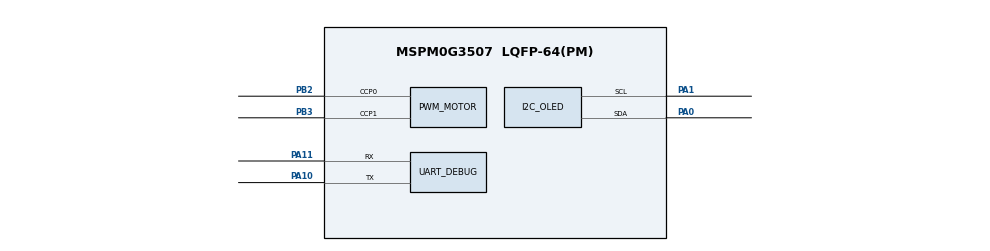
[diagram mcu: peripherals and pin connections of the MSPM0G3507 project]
/**
 * H2026 Q2 MSPM0G3507 peripheral ownership.
 *
 * This is a new hardware configuration for the frozen C07A/S27F-S28A
 * vehicle.  It is intentionally unrelated to the old generic-car SysConfig.
 */
//@cliArgs --device "MSPM0G350X" --package "LQFP-64(PM)" --part "Default"
//@v2CliArgs --device "MSPM0G3507" --package "LQFP-64(PM)"
// @cliArgs --board /ti/boards/LP_MSPM0G3507 --rtos nortos

const GPIO   = scripting.addModule("/ti/driverlib/GPIO", {}, false);
const PWM    = scripting.addModule("/ti/driverlib/PWM", {}, false);
const TIMER  = scripting.addModule("/ti/driverlib/TIMER", {}, false);
const UART   = scripting.addModule("/ti/driverlib/UART", {}, false);
const ADC12  = scripting.addModule("/ti/driverlib/ADC12", {}, false);
const I2C    = scripting.addModule("/ti/driverlib/I2C", {}, false);
const SYSCTL = scripting.addModule("/ti/driverlib/SYSCTL");

const PWM_MOTOR = PWM.addInstance();
const TIMER_CONTROL = TIMER.addInstance();
const UART_DEBUG = UART.addInstance();
const ADC_LINE_SENSOR = ADC12.addInstance();
const I2C_OLED = I2C.addInstance();

const GPIO_ENCODER_LEFT  = GPIO.addInstance();
const GPIO_ENCODER_RIGHT = GPIO.addInstance();
const GPIO_MOTOR_DIR     = GPIO.addInstance();
const GPIO_UI            = GPIO.addInstance();
const GPIO_LINE_MUX = GPIO.addInstance();

const Board = scripting.addModule("/ti/driverlib/Board", {}, false);

SYSCTL.forceDefaultClkConfig = true;
SYSCTL.clockTreeEn = true;

/* Integrated D103A/TB6612: PWMA/PWMB plus two GPIO direction pairs. */
PWM_MOTOR.$name = "PWM_MOTOR";
PWM_MOTOR.clockPrescale = 1;
PWM_MOTOR.timerCount = 8000;
PWM_MOTOR.timerStartTimer = false;
PWM_MOTOR.peripheral.$assign = "TIMA1";
PWM_MOTOR.peripheral.ccp0Pin.$assign = "PB2";
PWM_MOTOR.peripheral.ccp1Pin.$assign = "PB3";
PWM_MOTOR.PWM_CHANNEL_0.$name = "TB_A_PWM";
PWM_MOTOR.PWM_CHANNEL_0.dutyCycle = 0;
PWM_MOTOR.PWM_CHANNEL_1.$name = "TB_B_PWM";
PWM_MOTOR.PWM_CHANNEL_1.dutyCycle = 0;

/* Hard 5 ms scheduler source.  ISR only records pending/overrun counters. */
TIMER_CONTROL.$name = "TIMER_CONTROL";
TIMER_CONTROL.profile = "Basic_Periodic";
TIMER_CONTROL.timerPeriod = "5 ms";
TIMER_CONTROL.timerStartTimer = false;
TIMER_CONTROL.peripheral.$assign = "TIMG7";

/* CD4051 eight-channel gray board: AD2=PA12, AD1=PA27, AD0=PB16, OUT=PB17. */
GPIO_LINE_MUX.$name = "GPIO_LINE_MUX";
GPIO_LINE_MUX.associatedPins.create(3);
GPIO_LINE_MUX.associatedPins[0].$name = "LINE_AD2";
GPIO_LINE_MUX.associatedPins[0].assignedPort = "PORTA";
GPIO_LINE_MUX.associatedPins[0].assignedPin = "12";
GPIO_LINE_MUX.associatedPins[0].initialValue = "CLEARED";
GPIO_LINE_MUX.associatedPins[1].$name = "LINE_AD1";
GPIO_LINE_MUX.associatedPins[1].assignedPort = "PORTA";
GPIO_LINE_MUX.associatedPins[1].assignedPin = "27";
GPIO_LINE_MUX.associatedPins[1].initialValue = "CLEARED";
GPIO_LINE_MUX.associatedPins[2].$name = "LINE_AD0";
GPIO_LINE_MUX.associatedPins[2].assignedPort = "PORTB";
GPIO_LINE_MUX.associatedPins[2].assignedPin = "16";
GPIO_LINE_MUX.associatedPins[2].initialValue = "CLEARED";

ADC_LINE_SENSOR.$name = "ADC_LINE_SENSOR";
ADC_LINE_SENSOR.sampClkSrc = "DL_ADC12_CLOCK_ULPCLK";
ADC_LINE_SENSOR.sampClkDiv = "DL_ADC12_CLOCK_DIVIDE_8";
ADC_LINE_SENSOR.adcMem0chansel = "DL_ADC12_INPUT_CHAN_4";
/* Default supports the 1.2 ms scan budget; validate after any divider fit. */
ADC_LINE_SENSOR.sampleTime0 = "1us";
ADC_LINE_SENSOR.powerDownMode = "DL_ADC12_POWER_DOWN_MODE_MANUAL";
ADC_LINE_SENSOR.peripheral.$assign = "ADC1";
ADC_LINE_SENSOR.peripheral.adcPin4.$assign = "PB17";

/* External four-pin OLED and the retained MPU6050 share I2C0 safely. */
I2C_OLED.$name = "I2C_OLED";
I2C_OLED.basicEnableController = true;
I2C_OLED.basicControllerBusSpeed = 400000;
I2C_OLED.advAnalogGlitchFilter = "DISABLED";
I2C_OLED.peripheral.$assign = "I2C0";
I2C_OLED.peripheral.sdaPin.$assign = "PA0";
I2C_OLED.peripheral.sclPin.$assign = "PA1";

UART_DEBUG.$name = "UART_DEBUG";
UART_DEBUG.enableFIFO = true;
UART_DEBUG.enableDMARX = false;
UART_DEBUG.enableDMATX = false;
UART_DEBUG.targetBaudRate = 115200;
/* Dedicated debug serial path; it does not share the line-sensor bus. */
UART_DEBUG.peripheral.$assign = "UART0";
UART_DEBUG.peripheral.txPin.$assign = "PA10";
UART_DEBUG.peripheral.rxPin.$assign = "PA11";


/*
 * Both encoder phases use GPIO rise/fall interrupts (four-edge decoding).
 * C07A/S27F logical left is TB6612 channel B (PB20/PB24); logical right is
 * channel A (PA25/PA26).  This follows the bench-verified wheel mapping.
 */
GPIO_ENCODER_LEFT.$name = "GPIO_ENCODER_LEFT";
GPIO_ENCODER_LEFT.port = "PORTB";
GPIO_ENCODER_LEFT.associatedPins.create(2);
GPIO_ENCODER_LEFT.associatedPins[0].$name = "LEFT_A";
GPIO_ENCODER_LEFT.associatedPins[0].assignedPin = "20";
GPIO_ENCODER_LEFT.associatedPins[0].direction = "INPUT";
GPIO_ENCODER_LEFT.associatedPins[0].interruptEn = true;
GPIO_ENCODER_LEFT.associatedPins[0].polarity = "RISE_FALL";
GPIO_ENCODER_LEFT.associatedPins[1].$name = "LEFT_B";
GPIO_ENCODER_LEFT.associatedPins[1].assignedPin = "24";
GPIO_ENCODER_LEFT.associatedPins[1].direction = "INPUT";
GPIO_ENCODER_LEFT.associatedPins[1].interruptEn = true;
GPIO_ENCODER_LEFT.associatedPins[1].polarity = "RISE_FALL";

GPIO_ENCODER_RIGHT.$name = "GPIO_ENCODER_RIGHT";
GPIO_ENCODER_RIGHT.port = "PORTA";
GPIO_ENCODER_RIGHT.associatedPins.create(2);
GPIO_ENCODER_RIGHT.associatedPins[0].$name = "RIGHT_A";
GPIO_ENCODER_RIGHT.associatedPins[0].assignedPin = "25";
GPIO_ENCODER_RIGHT.associatedPins[0].direction = "INPUT";
GPIO_ENCODER_RIGHT.associatedPins[0].interruptEn = true;
GPIO_ENCODER_RIGHT.associatedPins[0].polarity = "RISE_FALL";
GPIO_ENCODER_RIGHT.associatedPins[1].$name = "RIGHT_B";
GPIO_ENCODER_RIGHT.associatedPins[1].assignedPin = "26";
GPIO_ENCODER_RIGHT.associatedPins[1].direction = "INPUT";
GPIO_ENCODER_RIGHT.associatedPins[1].interruptEn = true;
GPIO_ENCODER_RIGHT.associatedPins[1].polarity = "RISE_FALL";

/* D103A/TB6612 direction pins.  All four start low, which coasts both motors. */
GPIO_MOTOR_DIR.$name = "GPIO_MOTOR_DIR";
GPIO_MOTOR_DIR.associatedPins.create(4);
GPIO_MOTOR_DIR.associatedPins[0].$name = "TB_A_IN1";
GPIO_MOTOR_DIR.associatedPins[0].assignedPort = "PORTA";
GPIO_MOTOR_DIR.associatedPins[0].assignedPin = "14";
GPIO_MOTOR_DIR.associatedPins[0].initialValue = "CLEARED";
GPIO_MOTOR_DIR.associatedPins[1].$name = "TB_A_IN2";
GPIO_MOTOR_DIR.associatedPins[1].assignedPort = "PORTA";
GPIO_MOTOR_DIR.associatedPins[1].assignedPin = "13";
GPIO_MOTOR_DIR.associatedPins[1].initialValue = "CLEARED";
GPIO_MOTOR_DIR.associatedPins[2].$name = "TB_B_IN1";
GPIO_MOTOR_DIR.associatedPins[2].assignedPort = "PORTA";
GPIO_MOTOR_DIR.associatedPins[2].assignedPin = "16";
GPIO_MOTOR_DIR.associatedPins[2].initialValue = "CLEARED";
GPIO_MOTOR_DIR.associatedPins[3].$name = "TB_B_IN2";
GPIO_MOTOR_DIR.associatedPins[3].assignedPort = "PORTA";
GPIO_MOTOR_DIR.associatedPins[3].assignedPin = "17";
GPIO_MOTOR_DIR.associatedPins[3].initialValue = "CLEARED";

GPIO_UI.$name = "GPIO_UI";
GPIO_UI.associatedPins.create(2);
GPIO_UI.associatedPins[0].$name = "START";
GPIO_UI.associatedPins[0].assignedPort = "PORTA";
GPIO_UI.associatedPins[0].assignedPin = "18";
GPIO_UI.associatedPins[0].direction = "INPUT";
/* C07A SW3/BLS already has R8=47 kOhm external pull-down; pressing drives 3V3. */
GPIO_UI.associatedPins[0].internalResistor = "NONE";
GPIO_UI.associatedPins[1].$name = "STATUS_LED";
GPIO_UI.associatedPins[1].assignedPort = "PORTB";
GPIO_UI.associatedPins[1].assignedPin = "9";
GPIO_UI.associatedPins[1].initialValue = "CLEARED";
